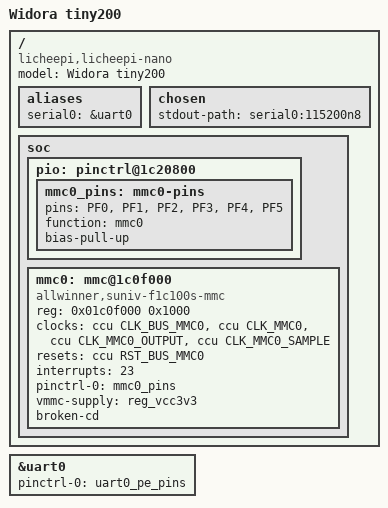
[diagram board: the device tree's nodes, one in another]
// SPDX-License-Identifier: (GPL-2.0+ OR X11)

/dts-v1/;
#include "suniv-f1c100s.dtsi"

#include "sunxi-common-regulators.dtsi"
#include <dt-bindings/clock/suniv-ccu-f1c100s.h>
#include <dt-bindings/reset/suniv-ccu-f1c100s.h>

/ {
	model = "Widora tiny200";
	compatible = "licheepi,licheepi-nano", "allwinner,suniv-f1c100s";

	aliases {
		serial0 = &uart0;
	};

	chosen {
		stdout-path = "serial0:115200n8";
	};

    soc {
        pio: pinctrl@1c20800 {
            mmc0_pins: mmc0-pins {
				pins = "PF0", "PF1", "PF2", "PF3", "PF4", "PF5";
				function = "mmc0";
				bias-pull-up;
			};
		};

        mmc0: mmc@1c0f000 {
			compatible = "allwinner,suniv-f1c100s-mmc",
					 "allwinner,sun7i-a20-mmc";
			reg = <0x01c0f000 0x1000>;
			clocks = <&ccu CLK_BUS_MMC0>,
				 <&ccu CLK_MMC0>,
				 <&ccu CLK_MMC0_OUTPUT>,
				 <&ccu CLK_MMC0_SAMPLE>;
			clock-names = "ahb",
					  "mmc",
					  "output",
					  "sample";
			resets = <&ccu RST_BUS_MMC0>;
			reset-names = "ahb";
			interrupts = <23>;
			pinctrl-0 = <&mmc0_pins>;
			pinctrl-names = "default";
			vmmc-supply = <&reg_vcc3v3>;
			broken-cd;
			status = "disabled";
			#address-cells = <1>;
			#size-cells = <0>;
		};
    };
};

&uart0 {
	pinctrl-names = "default";
	pinctrl-0 = <&uart0_pe_pins>;
	status = "okay";
};

&mmc0 {
	status = "okay";
	broken-cd;
};
